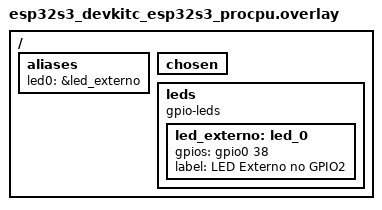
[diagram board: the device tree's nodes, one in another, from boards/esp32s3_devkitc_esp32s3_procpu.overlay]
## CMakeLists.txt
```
#
# Copyright (c) 2022 Nordic Semiconductor ASA
#
# SPDX-License-Identifier: LicenseRef-Nordic-5-Clause
#

cmake_minimum_required(VERSION 3.20.0)

find_package(Zephyr REQUIRED HINTS $ENV{ZEPHYR_BASE})
project(wifi_static)

target_sources(app PRIVATE src/main.c src/tago_post.c)
```

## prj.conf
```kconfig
# Logging, minimum without colors
CONFIG_LOG=y
CONFIG_LOG_MODE_MINIMAL=y

# GPIO Driver (already activated by minimum config)
CONFIG_GPIO=y

# # Wi-Fi
# # Enable the Wi-Fi relevant configurations
CONFIG_WIFI=y
# Disable Zephyr WPA since there is an external chip
# CONFIG_WIFI_NM_WPA_SUPPLICANT=n

# # Configure the Wi-Fi credentials
CONFIG_WIFI_CREDENTIALS=y
CONFIG_WIFI_CREDENTIALS_STATIC=y
CONFIG_WIFI_CREDENTIALS_STATIC_SSID="iot-juca"
CONFIG_WIFI_CREDENTIALS_STATIC_PASSWORD="gsypt88651"

# Enable the Network Management relevant configurations
# CONFIG_NET_MGMT=y
CONFIG_NET_MGMT_EVENT=y
#CONFIG_NET_MGMT_EVENT_INFO=y
CONFIG_NET_MGMT_EVENT_QUEUE_TIMEOUT=5000
CONFIG_NET_MGMT_EVENT_QUEUE_SIZE=16
CONFIG_NET_L2_WIFI_MGMT=y
# CONFIG_WIFI_LOG_LEVEL_DBG=y

# # Enable the Connection Manager 
CONFIG_NET_CONNECTION_MANAGER=y
# CONFIG_NET_CONNECTION_MANAGER_MONITOR_STACK_SIZE=5200

# # System settings
# CONFIG_NEWLIB_LIBC=y
# CONFIG_NEWLIB_LIBC_NANO=n

# # Networking
CONFIG_NETWORKING=y
CONFIG_TEST_RANDOM_GENERATOR=y
CONFIG_NET_L2_ETHERNET=y
CONFIG_NET_IPV4=y
CONFIG_NET_IPV6=n
CONFIG_NET_DHCPV4=y
CONFIG_NET_TCP=y
# Disable network shell
CONFIG_NET_SHELL=n
# Print network debug
CONFIG_NET_LOG=y

# Sockets
CONFIG_NET_SOCKETS=y
CONFIG_ZVFS_POLL_MAX=4

# # Memory
# CONFIG_SYSTEM_WORKQUEUE_STACK_SIZE=4096
CONFIG_MAIN_STACK_SIZE=5200
CONFIG_NET_TX_STACK_SIZE=2048
CONFIG_NET_RX_STACK_SIZE=2048

CONFIG_NET_MAX_CONTEXTS=16
CONFIG_NET_PKT_RX_COUNT=16
CONFIG_NET_PKT_TX_COUNT=16
CONFIG_NET_BUF_RX_COUNT=32
CONFIG_NET_BUF_TX_COUNT=32

# DNS
CONFIG_DNS_RESOLVER=y
CONFIG_DNS_RESOLVER_ADDITIONAL_BUF_CTR=2
CONFIG_DNS_RESOLVER_MAX_SERVERS=1
CONFIG_DNS_SERVER_IP_ADDRESSES=n
CONFIG_DNS_SERVER1="8.8.8.8"
CONFIG_NET_SOCKETS_DNS_TIMEOUT=5000
CONFIG_DNS_RESOLVER_LOG_LEVEL_DBG=n

# HTTP
CONFIG_HTTP_CLIENT=y
CONFIG_POSIX_API=y
```

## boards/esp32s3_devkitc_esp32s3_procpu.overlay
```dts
/ {
	aliases {
		led0 = &led_externo;
	};

	chosen {
		/* Change logs to JTAG USB */
        	//zephyr,console = &usb_serial;
        	//zephyr,shell-uart = &usb_serial;
    	};

	leds {
		compatible = "gpio-leds";

		led_externo: led_0 {
			gpios = <&gpio0 38 GPIO_ACTIVE_HIGH>;
			label = "LED Externo no GPIO2";
		};
	};
};

/* Activate JTAG USB */
//&usb_serial {
//    status = "okay";
//};
```

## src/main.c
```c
/**
 * @file main.c
 * @brief RP Pico W static Wi-Fi sample application using Zephyr OS.
 *
 * @details This file contains the implementation for connecting a board
 * (like the Raspberry Pi Pico W) to a Wi-Fi network using static credentials
 * defined in the project configuration. It utilizes Zephyr's network
 * management API and synchronization primitives to manage connection state.
 * After that, the applications sends data to Tago.IO using http post.
 */

/* C includes */
#include <errno.h>
#include <stddef.h>
#include <string.h>
#include <stdio.h>

/* Zephyr includes */
#include <zephyr/kernel.h>
#include <zephyr/types.h>
#include <zephyr/logging/log.h>

/* Wifi header files */
#include <zephyr/net/net_mgmt.h>
#include <zephyr/net/wifi_mgmt.h>
#include <zephyr/net/wifi_credentials.h>

/* Http includes */
#include <zephyr/net/http/client.h>

/* Local includes */
#include "tago_post.h"

LOG_MODULE_REGISTER(main, LOG_LEVEL_INF);

/**
 * @brief Macro defining the relevant network events to listen for.
 *
 * Mask includes Layer 4 (L4) connected and disconnected events.
 */
#define EVENT_MASK (NET_EVENT_L4_CONNECTED | NET_EVENT_L4_DISCONNECTED)

/**
 * @brief Callback structure for network management events.
 */
static struct net_mgmt_event_callback mgmt_cb;

/* Declare the variable for the network configuration parameters */
static struct wifi_connect_req_params cnx_params;

/**
 * @brief Flag indicating the current Wi-Fi connection status.
 *
 * True if connected to the network, false otherwise.
 */
static bool connected;

/**
 * @brief Semaphore used to block the application until a network connection is established.
 */
static K_SEM_DEFINE(run_app, 0, 1);

/**
 * @brief Callback handler for network management events.
 *
 * @details Handles Layer 4 (L4) connection and disconnection events. It updates
 * the `connected` flag and signals the `run_app` semaphore upon a successful
 * connection, or resets the semaphore upon disconnection.
 *
 * @param cb Pointer to the network management event callback structure.
 * @param mgmt_event The specific network management event that triggered the callback.
 * @param iface Pointer to the network interface where the event occurred.
 */
static void net_mgmt_event_handler(struct net_mgmt_event_callback *cb,
			  uint64_t mgmt_event, struct net_if *iface)
{	
	if ((mgmt_event & EVENT_MASK) != mgmt_event) {
		return;
	}

	if (mgmt_event == NET_EVENT_L4_CONNECTED) {
		LOG_INF("Network connected");
		connected = true;
		k_sem_give(&run_app);
		return;
	}
	if (mgmt_event == NET_EVENT_L4_DISCONNECTED) {
		if (connected == false) {
			LOG_INF("Waiting for network to be connected");
		} else {
			LOG_INF("Network disconnected");
			connected = false;
		}
		k_sem_reset(&run_app);
		return;
	}
}


/**
 * @brief Populates the Wi-Fi connection request parameters.
 *
 * @details Extracts the SSID and password from the Zephyr Kconfig definitions
 * (`CONFIG_WIFI_CREDENTIALS_STATIC_SSID` and `CONFIG_WIFI_CREDENTIALS_STATIC_PASSWORD`)
 * and populates the remaining connection parameters with generic defaults.
 *
 * @param params Pointer to the Wi-Fi connection request parameters structure to populate.
 * @return int Returns 0 on successful population.
 */
static int write_wifi_parameters(struct wifi_connect_req_params *params)
{

	/* Populate the SSID and password from prj.conf */
	params->ssid = CONFIG_WIFI_CREDENTIALS_STATIC_SSID;
	params->ssid_length = strlen(params->ssid);

	params->psk = CONFIG_WIFI_CREDENTIALS_STATIC_PASSWORD;
	params->psk_length = strlen(params->psk);

	/* Populate the rest of the relevant members */
	params->channel = WIFI_CHANNEL_ANY;
	params->security = WIFI_SECURITY_TYPE_PSK;
	params->mfp = WIFI_MFP_OPTIONAL;
	params->timeout = SYS_FOREVER_MS;
	params->band = WIFI_FREQ_BAND_UNKNOWN;
	memset(params->bssid, 0, sizeof(params->bssid));

	return 0;
}

/**
 * @brief Initializes the Wi-Fi driver and attempts connection.
 *
 * @details Sets up the necessary callbacks for monitoring Wi-Fi status, retrieves
 * the default Wi-Fi network interface, provisions it with static credentials, and
 * dispatches connection requests via `net_mgmt()`. The function polls every 5 seconds
 * if the connection fails and will ultimately block indefinitely until `run_app` is given.
 *
 * @return int Returns -1 if no Wi-Fi interface is found. Otherwise, blocks until connection.
 */
static int setup_wifi(){

	LOG_INF("Initializing Wi-Fi driver");
	/* Sleep to allow initialization of Wi-Fi driver */
	k_sleep(K_SECONDS(1));

	/* Initialize and add the callback function for network events */
	net_mgmt_init_event_callback(&mgmt_cb, net_mgmt_event_handler, EVENT_MASK);
	net_mgmt_add_event_callback(&mgmt_cb);

	/* Get the network interface */
	struct net_if *iface = net_if_get_first_wifi();
	if (iface == NULL) {
		LOG_ERR("Returned network interface is NULL");
		return -1;
	}

	/* Populate cnx_params with the network configuration */
	write_wifi_parameters(&cnx_params);

	/* Call net_mgmt() to request the Wi-Fi connection */
	int err;

	/* Try to connect */
	do {
		LOG_INF("Connecting to WiFi...");
		err = net_mgmt(NET_REQUEST_WIFI_CONNECT, iface, &cnx_params, sizeof(struct wifi_connect_req_params));

		if (err) {
			LOG_ERR("Connecting to Wi-Fi failed, err: %d", err);
			LOG_ERR("New try in 5s.");
			k_sleep(K_SECONDS(5));
		}
	} while (err != 0);

	LOG_INF("Waiting to connect!");

	/* Wait forever for a wifi connection.
	 * Unblocked by the callback funcion */
	k_sem_take(&run_app, K_FOREVER);

	return 0;
}


static int response_cb(struct http_response *rsp,
		       enum http_final_call final_data,
		       void *user_data)
{
	if (final_data == HTTP_DATA_MORE) {
		LOG_DBG("Partial data received (%zd bytes)", rsp->data_len);
	} else if (final_data == HTTP_DATA_FINAL) {
		LOG_DBG("All the data received (%zd bytes)", rsp->data_len);
	}

	LOG_DBG("Response status %s", rsp->http_status);

	return 0;
}



/**
 * @brief Main application entry point.
 *
 * @details Calls the Wi-Fi setup routine and then enters an infinite loop,
 * outputting a heartbeat message periodically to standard output.
 *
 * @return int Main exit status (does not normally return).
 */
int main(void)
{
	int temperature = 0;
	
	static struct tagoio_context ctx;

	LOG_INF("TagoIO post sample.");

	/* Try to connect to Wifi. Ths function does not return
	 * until a wifi connection is stablished.
	*/
	setup_wifi();


	int post = 3;
	while (post) {
		k_msleep(1000*10);
		LOG_INF("Posting data.");

		snprintf(ctx.payload, sizeof(ctx.payload),
		       "{\"variable\": \"temperature\","
		       "\"unit\": \"c\",\"value\": %d}",
		       temperature);

		if (tagoio_connect(&ctx) < 0) {
			LOG_ERR("No connection available.");
			continue;
		}
		
		if (tagoio_http_push(&ctx, response_cb) < 0) {
			LOG_ERR("Error pushing data.");
			continue;
		}

		LOG_INF("Post successful...");

		temperature += 2;	
		post--;
	}


	return 0;
}
```

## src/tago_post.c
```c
/**
 * @file tago_post.c
 * @brief HTTP POST implementation for transmitting telemetry data to the TagoIO cloud platform on Zephyr RTOS[cite: 1].
 * @author Gerson Fernando Budke <nandojve@gmail.com>[cite: 1]
 * @copyright Copyright (c) 2020 Gerson Fernando Budke[cite: 1]
 * @license Apache-2.0[cite: 1]
 *
 * @details This module manages the network lifecycle for sending JSON payloads to the 
 *          TagoIO HTTP data endpoint[cite: 1]. It handles DNS resolution with retry mechanisms,
 *          POSIX socket creation for IPv4/IPv6 configurations, and HTTP POST transmission[cite: 1].
 */

#include <zephyr/logging/log.h>
#include <zephyr/posix/netinet/in.h>
#include <zephyr/posix/sys/socket.h>
#include <zephyr/posix/arpa/inet.h>
#include <zephyr/posix/unistd.h>
#include <zephyr/posix/poll.h>
#include <zephyr/posix/netdb.h>

#include <zephyr/net/net_ip.h>
#include <zephyr/net/socket.h>
#include <zephyr/net/socketutils.h>
#include <zephyr/net/dns_resolve.h>
#include <zephyr/net/tls_credentials.h>
#include <zephyr/net/http/client.h>

#include "tago_post.h"

LOG_MODULE_DECLARE(tagoio_http_post, LOG_LEVEL_INF);

/** 
 * @def CONFIG_TAGOIO_DEVICE_TOKEN
 * @brief Unique device authorization token assigned by TagoIO for API authentication[cite: 1].
 */
#define CONFIG_TAGOIO_DEVICE_TOKEN "99ea1253-734f-4721-8e59-6a199b8ca70d"

/** 
 * @def TAGOIO_SERVER
 * @brief Fully qualified domain name (FQDN) for the TagoIO API server[cite: 1].
 */
#define TAGOIO_SERVER "api.tago.io"

/** 
 * @def TAGOIO_URL
 * @brief Target API HTTP endpoint path for posting data payloads[cite: 1].
 */
#define TAGOIO_URL          "/data"

/** 
 * @def HTTP_PORT
 * @brief Standard HTTP TCP port number string[cite: 1].
 */
#define HTTP_PORT           "80"

/** 
 * @def CONFIG_TAGOIO_HTTP_CONN_TIMEOUT
 * @brief Timeout duration in seconds for HTTP client request connection[cite: 1].
 */
#define CONFIG_TAGOIO_HTTP_CONN_TIMEOUT 10

/**
 * @brief HTTP header fields required for TagoIO API POST requests[cite: 1].
 *
 * Contains authorization token, content type specification, and SSL flag headers[cite: 1].
 * Terminated by a NULL pointer as expected by the HTTP client library[cite: 1].
 */
static const char *tagoio_http_headers[] = {
	"Device-Token: " CONFIG_TAGOIO_DEVICE_TOKEN "\r\n",
	"Content-Type: application/json\r\n",
	"_ssl: false\r\n",
	NULL
};

/**
 * @brief Resolves TagoIO server IP address and establishes a TCP socket connection[cite: 1].
 *
 * Performs DNS resolution for @ref TAGOIO_SERVER with up to 3 retries (5 seconds delay between attempts)[cite: 1].
 * Automatically configures IPv4 or IPv6 address family based on active network configuration[cite: 1].
 * Creates a stream socket and connects to the target server[cite: 1].
 *
 * @param[in,out] ctx Pointer to the @ref tagoio_context structure. Upon success, the 
 *                    established socket descriptor is stored in `ctx->sock`[cite: 1].
 *
 * @return 0 on success[cite: 1].
 * @return Negative standard errno code (`-errno`) on socket creation or connection failure[cite: 1].
 * @return Negative `getaddrinfo` error code on DNS resolution failure[cite: 1].
 */
int tagoio_connect(struct tagoio_context *ctx)
{
	struct addrinfo *addr;
	struct addrinfo hints;
	char hr_addr[INET6_ADDRSTRLEN];
	char *port;
	int dns_attempts = 3;
	int ret = -1;

	memset(&hints, 0, sizeof(hints));

	hints.ai_socktype = SOCK_STREAM;
	hints.ai_protocol = IPPROTO_TCP;
	if (IS_ENABLED(CONFIG_NET_IPV6)) {
		hints.ai_family = AF_INET6;
	} else if (IS_ENABLED(CONFIG_NET_IPV4)) {
		hints.ai_family = AF_INET;
	}
	port = HTTP_PORT;

	while (dns_attempts--) {
		ret = getaddrinfo(TAGOIO_SERVER, port, &hints, &addr);
				
		if (ret == 0) {
			break;
		}
		k_sleep(K_SECONDS(5));
	}

	if (ret < 0) {
		LOG_ERR("Could not resolve dns, error: %d", ret);
		return ret;
	}

	LOG_DBG("%s address: %s",
		(addr->ai_family == AF_INET ? "IPv4" : "IPv6"),
		net_addr_ntop(addr->ai_family,
			      &net_sin(addr->ai_addr)->sin_addr,
			      hr_addr, sizeof(hr_addr)));

	ctx->sock = socket(hints.ai_family,
			   hints.ai_socktype,
			   hints.ai_protocol);
	if (ctx->sock < 0) {
		LOG_ERR("Failed to create %s HTTP socket (%d)",
			(addr->ai_family == AF_INET ? "IPv4" : "IPv6"),
			-errno);

		freeaddrinfo(addr);
		return -errno;
	}

	if (connect(ctx->sock, addr->ai_addr, addr->ai_addrlen) < 0) {
		LOG_ERR("Cannot connect to %s remote (%d)",
			(addr->ai_family == AF_INET ? "IPv4" : "IPv6"),
			-errno);

		freeaddrinfo(addr);
		return -errno;
	}

	freeaddrinfo(addr);

	return 0;
}

/**
 * @brief Transmits stored JSON payload data via HTTP POST request to TagoIO[cite: 1].
 *
 * Prepares the Zephyr HTTP request structure with host info, headers, and payload from `ctx`[cite: 1].
 * Sends the request over the open socket, invokes the response callback, and closes the socket[cite: 1].
 *
 * @param[in,out] ctx Pointer to the @ref tagoio_context containing valid `sock`, `payload`, 
 *                    and `resp` receive buffer[cite: 1]. Socket is closed and set to `-1` upon return[cite: 1].
 * @param[in] resp_cb Callback function of type `http_response_cb_t` to handle server HTTP responses[cite: 1].
 *
 * @return 0 on successfully sending request and receiving complete response[cite: 1].
 * @return Negative error code returned by `http_client_req()` on transmission failure[cite: 1].
 */
int tagoio_http_push(struct tagoio_context *ctx,
		     http_response_cb_t resp_cb)
{
	struct http_request req;
	int ret;

	memset(&req, 0, sizeof(req));

	req.method		= HTTP_POST;
	req.host		= TAGOIO_SERVER;
	req.port		= HTTP_PORT;
	req.url			= TAGOIO_URL;
	req.header_fields	= tagoio_http_headers;
	req.protocol		= "HTTP/1.1";
	req.response		= resp_cb;
	req.payload		= ctx->payload;
	req.payload_len		= strlen(ctx->payload);
	req.recv_buf		= ctx->resp;
	req.recv_buf_len	= sizeof(ctx->resp);

	ret = http_client_req(ctx->sock, &req,
			      CONFIG_TAGOIO_HTTP_CONN_TIMEOUT * MSEC_PER_SEC,
			      ctx);

	close(ctx->sock);
	ctx->sock = -1;

	return ret;
}
```

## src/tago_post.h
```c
#ifndef __TAGO_POST_H__
#define __TAGO_POST_H__


#define TAGOIO_SOCKET_MAX_BUF_LEN 1280

struct tagoio_context {
	int sock;
	uint8_t payload[TAGOIO_SOCKET_MAX_BUF_LEN];
	uint8_t resp[TAGOIO_SOCKET_MAX_BUF_LEN];
};

int tagoio_connect(struct tagoio_context *ctx);
int tagoio_http_push(struct tagoio_context *ctx,
		     http_response_cb_t resp_cb);



#endif //__TAGO_POST_H__
```
